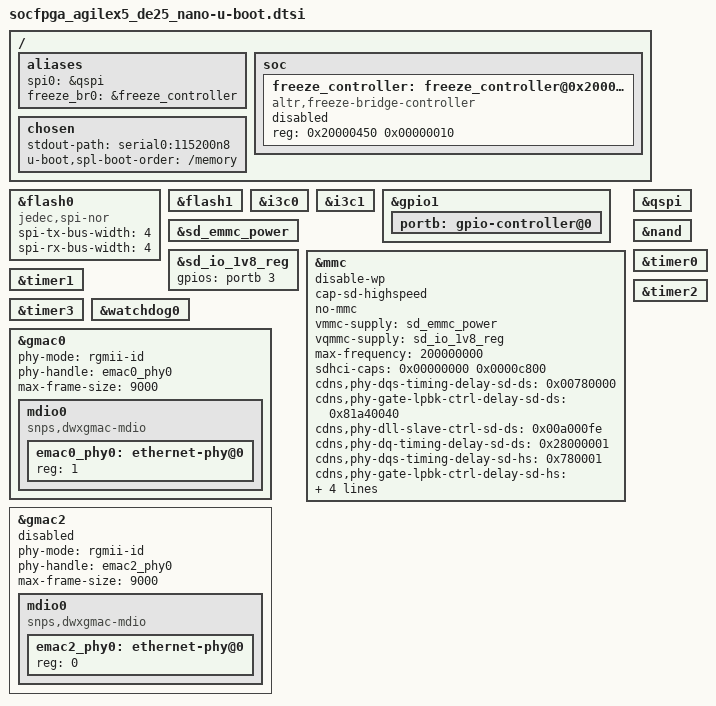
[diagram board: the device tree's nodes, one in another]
// SPDX-License-Identifier: GPL-2.0+
/*
 * U-Boot additions
 *
 * Copyright (C) 2026 Altera Corporation <www.altera.com>
 */

#include "socfpga_agilex5-u-boot.dtsi"

/{
	aliases {
		spi0 = &qspi;
		freeze_br0 = &freeze_controller;
	};

	soc {
		freeze_controller: freeze_controller@0x20000450 {
			compatible = "altr,freeze-bridge-controller";
			reg = <0x20000450 0x00000010>;
			status = "disabled";
		};
	};

	chosen {
		stdout-path = "serial0:115200n8";
		u-boot,spl-boot-order = &mmc,&flash0,&nand,"/memory";
	};
};

&flash0 {
	compatible = "jedec,spi-nor";
	spi-tx-bus-width = <4>;
	spi-rx-bus-width = <4>;
	bootph-all;
	/delete-property/ cdns,read-delay;
};

&flash1 {
	bootph-all;
};

&i3c0 {
	bootph-all;
};

&i3c1 {
	bootph-all;
};

&gpio1 {
	portb: gpio-controller@0 {
		bootph-all;
	};
};

&sd_emmc_power {
	bootph-all;
};

&sd_io_1v8_reg {
	gpios = <&portb 3 GPIO_ACTIVE_HIGH>;
	bootph-all;
};

&mmc {
	status = "okay";
	disable-wp;
	cap-sd-highspeed;
	no-mmc;
	vmmc-supply = <&sd_emmc_power>;
	vqmmc-supply = <&sd_io_1v8_reg>;
	max-frequency = <200000000>;
	sdhci-caps = <0x00000000 0x0000c800>;
	/* SD card default speed (DS) and UHS-I SDR12 mode timing configuration */
	cdns,phy-dqs-timing-delay-sd-ds = <0x00780000>;
	cdns,phy-gate-lpbk-ctrl-delay-sd-ds = <0x81a40040>;
	cdns,phy-dll-slave-ctrl-sd-ds = <0x00a000fe>;
	cdns,phy-dq-timing-delay-sd-ds = <0x28000001>;
	/* SD card high speed and UHS-I SDR25 mode timing configuration */
	cdns,phy-dqs-timing-delay-sd-hs = <0x780001>;
	cdns,phy-gate-lpbk-ctrl-delay-sd-hs = <0x81a40040>;
	cdns,phy-dq-timing-delay-sd-hs = <0x10000001>;
	cdns,ctrl-hrs16-slave-ctrl-sd-hs = <0x101>;
	cdns,ctrl-hrs07-timing-delay-sd-hs = <0xA0001>;
	bootph-all;
};

&qspi {
	status = "okay";
};

&nand {
	bootph-all;
};

&timer0 {
	bootph-all;
};

&timer1 {
	bootph-all;
};

&timer2 {
	bootph-all;
};

&timer3 {
	bootph-all;
};

&watchdog0 {
	bootph-all;
};

&gmac0 {
	status = "okay";
	phy-mode = "rgmii-id";
	phy-handle = <&emac0_phy0>;

	max-frame-size = <9000>;

	mdio0 {
		#address-cells = <1>;
		#size-cells = <0>;
		compatible = "snps,dwxgmac-mdio";
		emac0_phy0: ethernet-phy@0 {
			reg = <1>;
		};
	};
};

&gmac2 {
	status = "disabled";
	phy-mode = "rgmii-id";
	phy-handle = <&emac2_phy0>;

	max-frame-size = <9000>;

	mdio0 {
		#address-cells = <1>;
		#size-cells = <0>;
		compatible = "snps,dwxgmac-mdio";
		emac2_phy0: ethernet-phy@0 {
			reg = <0>;
		};
	};
};
